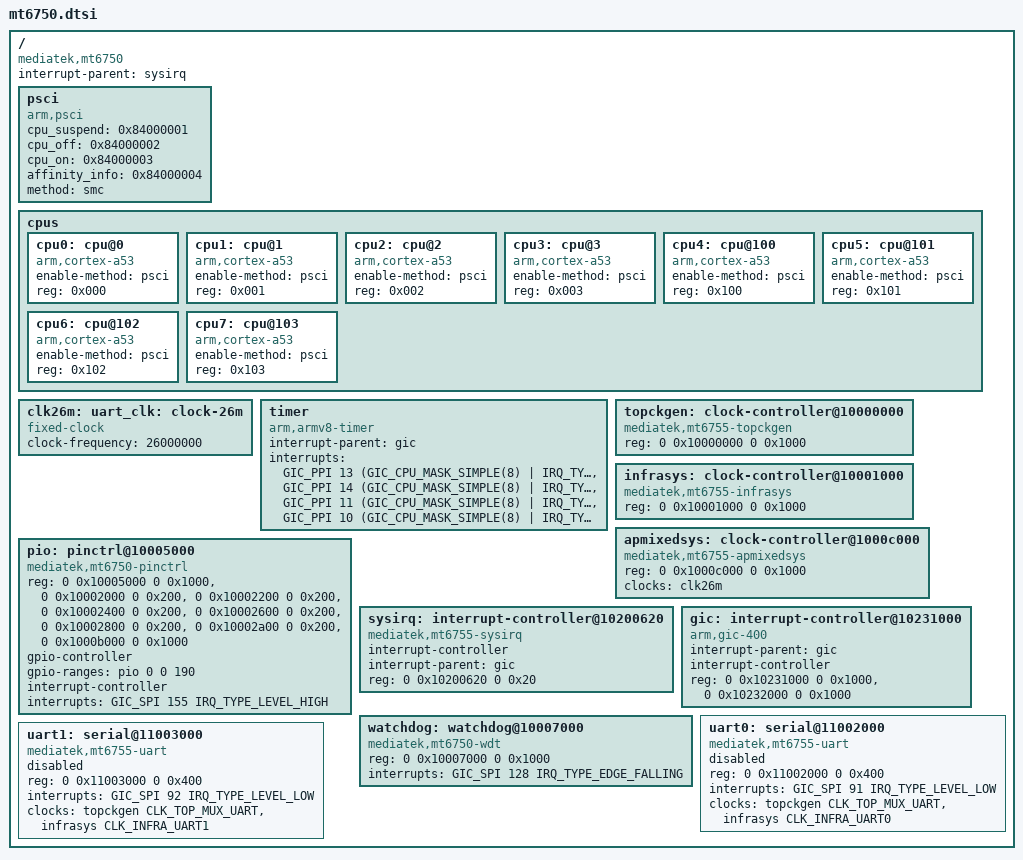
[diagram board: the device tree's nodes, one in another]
// SPDX-License-Identifier: GPL-2.0-only
/*
 * Copyright (c) 2016 MediaTek Inc.
 * Author: Mars.C <mars.cheng@mediatek.com>
 */

#include <dt-bindings/clock/mediatek,mt6755-clk.h>
#include <dt-bindings/interrupt-controller/irq.h>
#include <dt-bindings/interrupt-controller/arm-gic.h>

/ {
	compatible = "mediatek,mt6750";
	interrupt-parent = <&sysirq>;
	#address-cells = <2>;
	#size-cells = <2>;

	psci {
		compatible = "arm,psci";
		cpu_suspend = <0x84000001>;
		cpu_off = <0x84000002>;
		cpu_on = <0x84000003>;
		affinity_info = <0x84000004>;
		method = "smc";
	};

	cpus {
		#address-cells = <1>;
		#size-cells = <0>;

		cpu0: cpu@0 {
			device_type = "cpu";
			compatible = "arm,cortex-a53";
			enable-method = "psci";
			reg = <0x000>;
		};

		cpu1: cpu@1 {
			device_type = "cpu";
			compatible = "arm,cortex-a53";
			enable-method = "psci";
			reg = <0x001>;
		};

		cpu2: cpu@2 {
			device_type = "cpu";
			compatible = "arm,cortex-a53";
			enable-method = "psci";
			reg = <0x002>;
		};

		cpu3: cpu@3 {
			device_type = "cpu";
			compatible = "arm,cortex-a53";
			enable-method = "psci";
			reg = <0x003>;
		};

		cpu4: cpu@100 {
			device_type = "cpu";
			compatible = "arm,cortex-a53";
			enable-method = "psci";
			reg = <0x100>;
		};

		cpu5: cpu@101 {
			device_type = "cpu";
			compatible = "arm,cortex-a53";
			enable-method = "psci";
			reg = <0x101>;
		};

		cpu6: cpu@102 {
			device_type = "cpu";
			compatible = "arm,cortex-a53";
			enable-method = "psci";
			reg = <0x102>;
		};

		cpu7: cpu@103 {
			device_type = "cpu";
			compatible = "arm,cortex-a53";
			enable-method = "psci";
			reg = <0x103>;
		};
	};

	clk26m: uart_clk: clock-26m {
		compatible = "fixed-clock";
		clock-frequency = <26000000>;
		#clock-cells = <0>;
	};

	timer {
		compatible = "arm,armv8-timer";
		interrupt-parent = <&gic>;
		interrupts = <GIC_PPI 13
			     (GIC_CPU_MASK_SIMPLE(8) | IRQ_TYPE_LEVEL_LOW)>,
			     <GIC_PPI 14
			     (GIC_CPU_MASK_SIMPLE(8) | IRQ_TYPE_LEVEL_LOW)>,
			     <GIC_PPI 11
			     (GIC_CPU_MASK_SIMPLE(8) | IRQ_TYPE_LEVEL_LOW)>,
			     <GIC_PPI 10
			     (GIC_CPU_MASK_SIMPLE(8) | IRQ_TYPE_LEVEL_LOW)>;
	};

	topckgen: clock-controller@10000000 {
		compatible = "mediatek,mt6755-topckgen", "syscon";
		reg = <0 0x10000000 0 0x1000>;
		#clock-cells = <1>;
	};

	infrasys: clock-controller@10001000 {
		compatible = "mediatek,mt6755-infrasys", "syscon";
		reg = <0 0x10001000 0 0x1000>;
		#clock-cells = <1>;
	};

	apmixedsys: clock-controller@1000c000 {
		compatible = "mediatek,mt6755-apmixedsys";
		reg = <0 0x1000c000 0 0x1000>;
		clocks = <&clk26m>;
		clock-names = "clk26m";
		#clock-cells = <1>;
	};

	pio: pinctrl@10005000 {
		compatible = "mediatek,mt6750-pinctrl";
		reg = <0 0x10005000 0 0x1000>,
		      <0 0x10002000 0 0x200>,
		      <0 0x10002200 0 0x200>,
		      <0 0x10002400 0 0x200>,
		      <0 0x10002600 0 0x200>,
		      <0 0x10002800 0 0x200>,
		      <0 0x10002a00 0 0x200>,
		      <0 0x1000b000 0 0x1000>;
		reg-names = "gpio", "iocfg0", "iocfg1", "iocfg2",
			    "iocfg3", "iocfg4", "iocfg5", "eint";
		gpio-controller;
		#gpio-cells = <2>;
		gpio-ranges = <&pio 0 0 190>;
		interrupt-controller;
		#address-cells = <0>;
		#interrupt-cells = <2>;
		interrupts = <GIC_SPI 155 IRQ_TYPE_LEVEL_HIGH>;
	};

	sysirq: interrupt-controller@10200620 {
		compatible = "mediatek,mt6755-sysirq",
			     "mediatek,mt6577-sysirq";
		interrupt-controller;
		#address-cells = <0>;
		#interrupt-cells = <3>;
		interrupt-parent = <&gic>;
		reg = <0 0x10200620 0 0x20>;
	};

	gic: interrupt-controller@10231000 {
		compatible = "arm,gic-400";
		#interrupt-cells = <3>;
		interrupt-parent = <&gic>;
		interrupt-controller;
		#address-cells = <0>;
		reg = <0 0x10231000 0 0x1000>,
		      <0 0x10232000 0 0x1000>;
	};

	watchdog: watchdog@10007000 {
		compatible = "mediatek,mt6750-wdt";
		reg = <0 0x10007000 0 0x1000>;
		interrupts = <GIC_SPI 128 IRQ_TYPE_EDGE_FALLING>;
	};

	uart0: serial@11002000 {
		compatible = "mediatek,mt6755-uart",
			     "mediatek,mt6577-uart";
		reg = <0 0x11002000 0 0x400>;
		interrupts = <GIC_SPI 91 IRQ_TYPE_LEVEL_LOW>;
		clocks = <&topckgen CLK_TOP_MUX_UART>,
			 <&infrasys CLK_INFRA_UART0>;
		clock-names = "baud", "bus";
		status = "disabled";
	};

	uart1: serial@11003000 {
		compatible = "mediatek,mt6755-uart",
			     "mediatek,mt6577-uart";
		reg = <0 0x11003000 0 0x400>;
		interrupts = <GIC_SPI 92 IRQ_TYPE_LEVEL_LOW>;
		clocks = <&topckgen CLK_TOP_MUX_UART>,
			 <&infrasys CLK_INFRA_UART1>;
		clock-names = "baud", "bus";
		status = "disabled";
	};
};
